VERSION ""

NS_ :

BS_:

BU_: XXX

BO_ 385 ENGINE_DATA_1: 8 XXX
 SG_ RPM : 7|16@0+ (0.125,0) [0|8000] "R/min" XXX

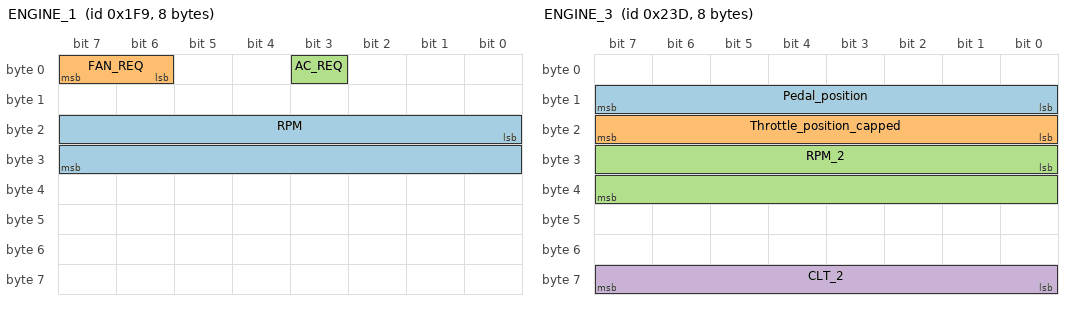
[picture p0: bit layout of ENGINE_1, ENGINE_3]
BO_ 505 ENGINE_1: 8 XXX
 SG_ RPM : 16|16@1+ (0.125,0) [0|8000] "R/min" XXX
 SG_ FAN_REQ : 6|2@1+ (1,0) [0|3] "" XXX
 SG_ AC_REQ : 3|1@1+ (1,0) [0|1] "" XXX

BO_ 573 ENGINE_3: 8 XXX
 SG_ Pedal_position : 8|8@1+ (0.392,0) [0|100] "%" XXX
 SG_ Throttle_position_capped : 16|8@1+ (0.392,0) [0|100] "%" XXX
 SG_ RPM_2 : 24|16@1+ (3.15,0) [0|8000] "R/min" XXX
 SG_ CLT_2 : 56|8@1+ (0.366666,0) [0|255] "C" XXX

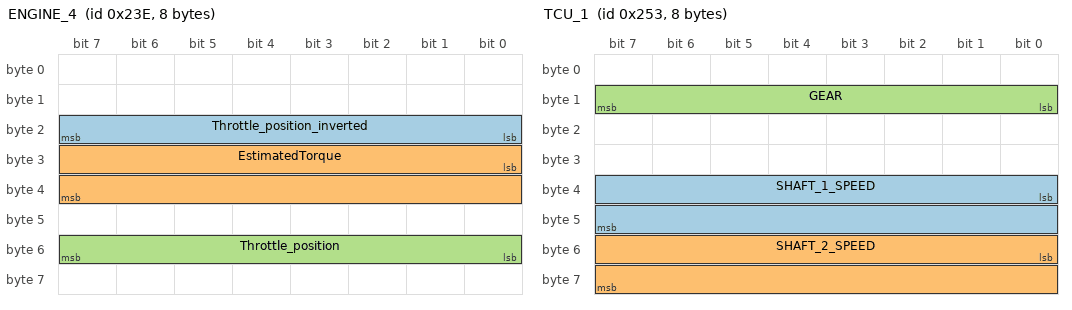
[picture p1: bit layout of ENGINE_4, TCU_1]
BO_ 574 ENGINE_4: 8 XXX
 SG_ Throttle_position_inverted : 16|8@1+ (0.392,0) [0|100] "%" XXX
 SG_ EstimatedTorque : 24|16@1+ (0.1,0) [0|45000] "nM" XXX
 SG_ Throttle_position : 48|8@1+ (0.392,0) [0|100] "%" XXX

BO_ 595 TCU_1: 8 XXX
 SG_ SHAFT_1_SPEED : 32|16@1+ (1,0) [0|45000] "r/min" XXX
 SG_ SHAFT_2_SPEED : 48|16@1+ (1,0) [0|45000] "r/min" XXX
 SG_ GEAR : 8|8@1+ (1,0) [0|15] "" XXX

BO_ 640 SPEED: 8 XXX
 SG_ SPEED : 32|16@1+ (0.01,0) [0|250] "km/h" XXX

BO_ 1361 ENGINE_5: 8 XXX
 SG_ CLT : 0|8@1+ (1,-45) [-45|150] "C" XXX

BO_ 1408 ENGINE_6: 8 XXX
 SG_ RPM_3 : 7|16@0+ (1.5,0) [0|8000] "R/min" XXX
 SG_ OIL_TEMP : 32|8@1+ (1,-40) [-40|150] "C" XXX

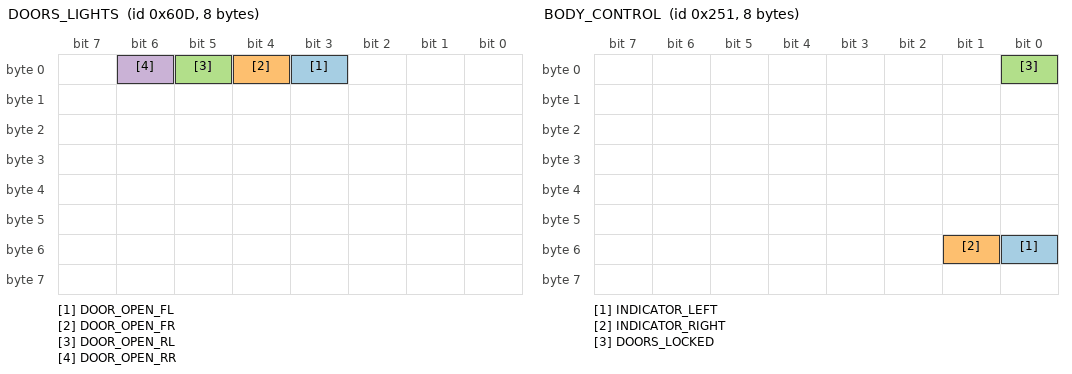
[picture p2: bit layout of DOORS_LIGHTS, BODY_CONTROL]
BO_ 1549 DOORS_LIGHTS: 8 XXX
 SG_ DOOR_OPEN_FL : 3|1@0+ (1,0) [0|1] "" XXX
 SG_ DOOR_OPEN_FR : 4|1@0+ (1,0) [0|1] "" XXX
 SG_ DOOR_OPEN_RL : 5|1@0+ (1,0) [0|1] "" XXX
 SG_ DOOR_OPEN_RR : 6|1@0+ (1,0) [0|1] "" XXX

BO_ 593 BODY_CONTROL: 8 XXX
 SG_ INDICATOR_LEFT : 48|1@1+ (1,0) [0|1] "" XXX
 SG_ INDICATOR_RIGHT : 49|1@1+ (1,0) [0|1] "" XXX
 SG_ DOORS_LOCKED : 0|1@1+ (1,0) [0|1] "" XXX

BO_ 1477 MILEAGE: 8 XXX
 SG_ ODOMETER : 0|24@1+ (1,0) [0|1000000] "km" XXX

BO_ 734 HVAC: 8 XXX
 SG_ CABIN_TEMP_SET : 8|8@1+ (0.5,15) [15|30] "C" XXX
 SG_ BLOWER_SPEED : 16|8@1+ (1,0) [0|7] "" XXX

BO_ 856 LIGHTS: 8 XXX
 SG_ HEADLIGHTS : 0|1@1+ (1,0) [0|1] "" XXX
 SG_ HIGH_BEAM : 1|1@1+ (1,0) [0|1] "" XXX

BO_ 768 STEERING: 8 XXX
 SG_ STEERING_ANGLE : 0|16@1- (0.1,0) [-360|360] "deg" XXX
